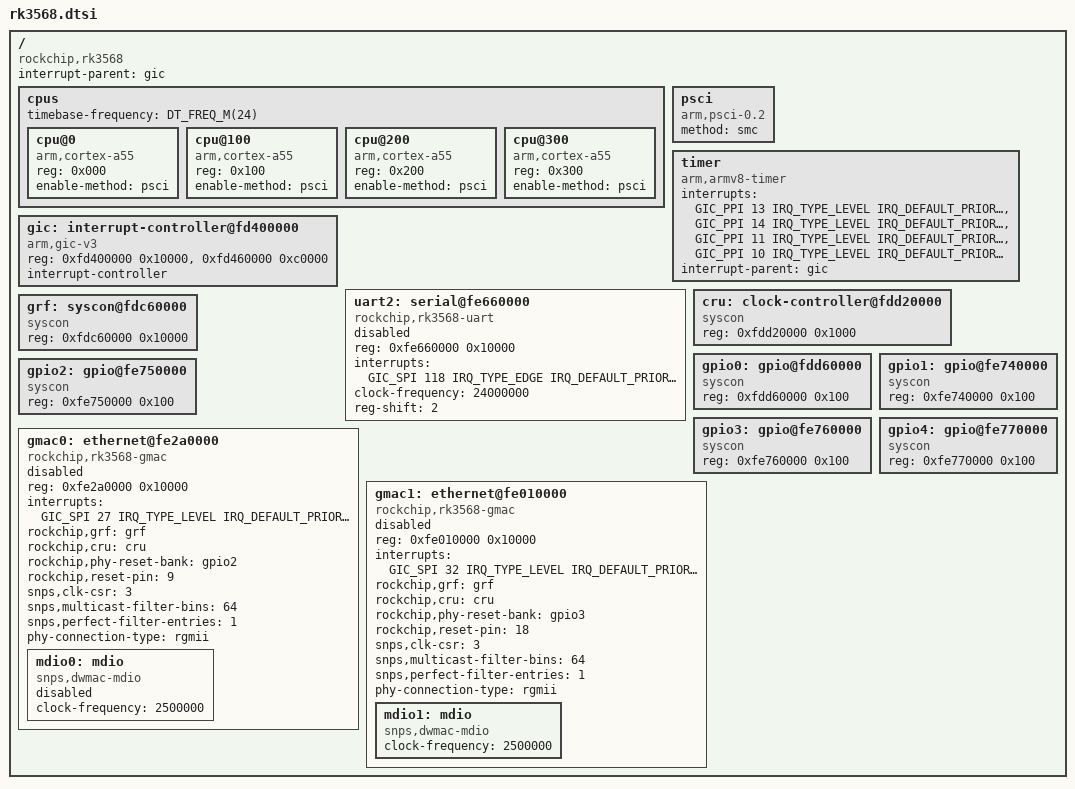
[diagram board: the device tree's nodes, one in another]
/*
 * Copyright 2020 NXP
 * Copyright 2022 HNU-ESNL
 * Copyright 2022 openEuler SIG-Zephyr
 *
 * SPDX-License-Identifier: Apache-2.0
 */

#include <freq.h>
#include <mem.h>
#include <arm64/armv8-a.dtsi>
#include <zephyr/dt-bindings/interrupt-controller/arm-gic.h>

/ {
	compatible = "rockchip,rk3568";
	#address-cells = <1>;
	#size-cells = <1>;
	interrupt-parent = <&gic>;

	cpus {
		#address-cells = <1>;
		#size-cells = <0>;
		timebase-frequency = <DT_FREQ_M(24)>;

		cpu@0 {
			compatible = "arm,cortex-a55";
			reg = <0x000>;
			device_type = "cpu";
			enable-method = "psci";
		};

		cpu@100 {
			compatible = "arm,cortex-a55";
			reg = <0x100>;
			device_type = "cpu";
			enable-method = "psci";
		};

		cpu@200 {
			compatible = "arm,cortex-a55";
			reg = <0x200>;
			device_type = "cpu";
			enable-method = "psci";
		};

		cpu@300 {
			compatible = "arm,cortex-a55";
			reg = <0x300>;
			device_type = "cpu";
			enable-method = "psci";
		};
	};

	psci {
		compatible = "arm,psci-0.2", "arm,psci";
		method = "smc";
	};

	timer {
		compatible = "arm,armv8-timer";
		interrupts = <GIC_PPI 13 IRQ_TYPE_LEVEL IRQ_DEFAULT_PRIORITY>,
			     <GIC_PPI 14 IRQ_TYPE_LEVEL IRQ_DEFAULT_PRIORITY>,
			     <GIC_PPI 11 IRQ_TYPE_LEVEL IRQ_DEFAULT_PRIORITY>,
			     <GIC_PPI 10 IRQ_TYPE_LEVEL IRQ_DEFAULT_PRIORITY>;
		interrupt-parent = <&gic>;
	};

	gic: interrupt-controller@fd400000 {
		compatible = "arm,gic-v3", "arm,gic";

		reg = <0xfd400000 0x10000>, /* GICD */
		      <0xfd460000 0xc0000>; /* GICR */
		#address-cells = <1>;
		#interrupt-cells = <4>;
		interrupt-controller;
		status = "okay";
	};

	uart2: serial@fe660000 {
		compatible = "rockchip,rk3568-uart", "ns16550";
		reg = <0xfe660000 0x10000>;
		interrupts = <GIC_SPI 118 IRQ_TYPE_EDGE IRQ_DEFAULT_PRIORITY>;
		/* SCLK_UART2 comes from the 24 MHz reference. */
		clock-frequency = <24000000>;
		reg-shift = <2>;
		status = "disabled";
	};

	/*
	 * There are no clock, pinctrl or GPIO drivers for RK3568 in the tree.
	 * The GMAC driver programs the CRU and GRF registers, and the PHY
	 * reset line, through the syscon mappings below.
	 */
	cru: clock-controller@fdd20000 {
		compatible = "syscon";
		reg = <0xfdd20000 0x1000>;
	};

	grf: syscon@fdc60000 {
		compatible = "syscon";
		reg = <0xfdc60000 0x10000>;
	};

	gpio0: gpio@fdd60000 {
		compatible = "syscon";
		reg = <0xfdd60000 0x100>;
	};

	gpio1: gpio@fe740000 {
		compatible = "syscon";
		reg = <0xfe740000 0x100>;
	};

	gpio2: gpio@fe750000 {
		compatible = "syscon";
		reg = <0xfe750000 0x100>;
	};

	gpio3: gpio@fe760000 {
		compatible = "syscon";
		reg = <0xfe760000 0x100>;
	};

	gpio4: gpio@fe770000 {
		compatible = "syscon";
		reg = <0xfe770000 0x100>;
	};

	gmac0: ethernet@fe2a0000 {
		compatible = "rockchip,rk3568-gmac", "snps,dwmac";
		reg = <0xfe2a0000 0x10000>;
		interrupts = <GIC_SPI 27 IRQ_TYPE_LEVEL IRQ_DEFAULT_PRIORITY>;
		rockchip,grf = <&grf>;
		rockchip,cru = <&cru>;
		rockchip,phy-reset-bank = <&gpio2>;
		rockchip,reset-pin = <9>;
		snps,clk-csr = <3>;
		snps,multicast-filter-bins = <64>;
		snps,perfect-filter-entries = <1>;
		phy-connection-type = "rgmii";
		status = "disabled";

		mdio0: mdio {
			compatible = "snps,dwmac-mdio";
			#address-cells = <1>;
			#size-cells = <0>;
			clock-frequency = <2500000>;
			status = "disabled";
		};
	};

	gmac1: ethernet@fe010000 {
		compatible = "rockchip,rk3568-gmac", "snps,dwmac";
		reg = <0xfe010000 0x10000>;
		interrupts = <GIC_SPI 32 IRQ_TYPE_LEVEL IRQ_DEFAULT_PRIORITY>;
		rockchip,grf = <&grf>;
		rockchip,cru = <&cru>;
		rockchip,phy-reset-bank = <&gpio3>;
		rockchip,reset-pin = <18>;
		snps,clk-csr = <3>;
		snps,multicast-filter-bins = <64>;
		snps,perfect-filter-entries = <1>;
		phy-connection-type = "rgmii";
		status = "disabled";

		mdio1: mdio {
			compatible = "snps,dwmac-mdio";
			#address-cells = <1>;
			#size-cells = <0>;
			clock-frequency = <2500000>;
		};
	};
};
